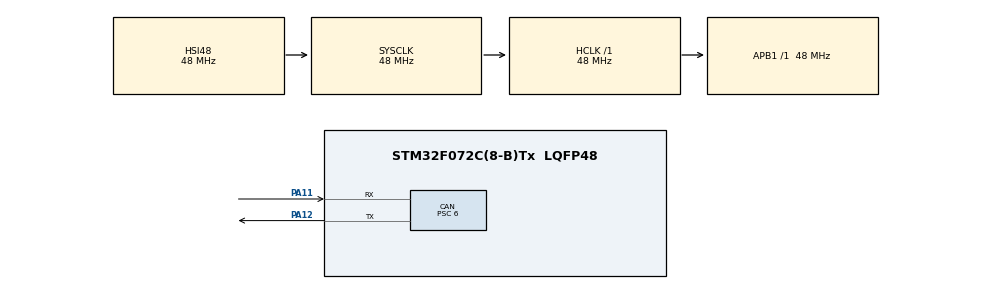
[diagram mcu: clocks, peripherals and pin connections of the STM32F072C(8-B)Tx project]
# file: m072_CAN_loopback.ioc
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CAN.BS1=CAN_BS1_13TQ
CAN.BS2=CAN_BS2_2TQ
CAN.CalculateBaudRate=500000
CAN.CalculateTimeBit=2000
CAN.CalculateTimeQuantum=125.0
CAN.Mode=CAN_MODE_LOOPBACK
CAN.Prescaler=6
Mcu.Family=STM32F0
Mcu.Name=STM32F072C(8-B)Tx
Mcu.Package=LQFP48
NVIC.CEC_CAN_IRQn=true\:0\:0\:false\:false\:true\:true\:true\:true
PA11.Mode=CAN_Activate
PA11.Signal=CAN_RX
PA12.Mode=CAN_Activate
PA12.Signal=CAN_TX
PA13.Mode=Serial_Wire
PA13.Signal=SYS_SWDIO
PA14.Mode=Serial_Wire
PA14.Signal=SYS_SWCLK
PF0-OSC_IN.Mode=HSE-External-Oscillator
PF0-OSC_IN.Signal=RCC_OSC_IN
PF1-OSC_OUT.Mode=HSE-External-Oscillator
PF1-OSC_OUT.Signal=RCC_OSC_OUT
ProjectManager.HeapSize=0x200
ProjectManager.StackSize=0x400
ProjectManager.TargetToolchain=STM32CubeIDE
RCC.AHBFreq_Value=48000000
RCC.APB1Freq_Value=48000000
RCC.APB1TimFreq_Value=48000000
RCC.HCLKFreq_Value=48000000
RCC.SYSCLKFreq_VALUE=48000000
RCC.SYSCLKSource=RCC_SYSCLKSOURCE_HSI48
board=custom

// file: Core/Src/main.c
/* USER CODE BEGIN Header */
/**
  ******************************************************************************
  * @file           : main.c
  * @brief          : Main program body
  ******************************************************************************
  * @attention
  *
  * Copyright (c) 2025 STMicroelectronics.
  * All rights reserved.
  *
  * This software is licensed under terms that can be found in the LICENSE file
  * in the root directory of this software component.
  * If no LICENSE file comes with this software, it is provided AS-IS.
  *
  ******************************************************************************
  */
/* USER CODE END Header */
#include "main.h"

/* USER CODE BEGIN Includes */

#include <string.h>

/* USER CODE END Includes */

CAN_HandleTypeDef hcan;

/* USER CODE BEGIN PV */

CAN_TxHeaderTypeDef TxHeader;
CAN_RxHeaderTypeDef RxHeader;
uint8_t TxData[8] = "STM32CAN";
uint8_t RxData[8];
uint32_t TxMailbox;

/* USER CODE END PV */

void SystemClock_Config(void);
static void MX_GPIO_Init(void);
static void MX_CAN_Init(void);

int main(void)
{

  /* MCU Configuration--------------------------------------------------------*/

  /* Reset of all peripherals, Initializes the Flash interface and the Systick. */
  HAL_Init();

  /* Configure the system clock */
  SystemClock_Config();

  /* Initialize all configured peripherals */
  MX_GPIO_Init();
  MX_CAN_Init();
  /* USER CODE BEGIN 2 */

  // Start the CAN peripheral
  HAL_CAN_Start(&hcan);

  // Enable interrupt for incoming messages
  HAL_CAN_ActivateNotification(&hcan, CAN_IT_RX_FIFO0_MSG_PENDING);

  // Configure filter to receive all messages
  CAN_FilterTypeDef sFilterConfig;
  sFilterConfig.FilterBank = 0;
  sFilterConfig.FilterMode = CAN_FILTERMODE_IDMASK;
  sFilterConfig.FilterScale = CAN_FILTERSCALE_32BIT;
  sFilterConfig.FilterIdHigh = 0x0000;
  sFilterConfig.FilterIdLow = 0x0000;
  sFilterConfig.FilterMaskIdHigh = 0x0000;
  sFilterConfig.FilterMaskIdLow = 0x0000;
  sFilterConfig.FilterFIFOAssignment = CAN_RX_FIFO0;
  sFilterConfig.FilterActivation = ENABLE;
  sFilterConfig.SlaveStartFilterBank = 14;
  HAL_CAN_ConfigFilter(&hcan, &sFilterConfig);

  // Prepare CAN message
  TxHeader.DLC = 8;
  TxHeader.IDE = CAN_ID_STD;
  TxHeader.RTR = CAN_RTR_DATA;
  TxHeader.StdId = 0x321;
  TxHeader.TransmitGlobalTime = DISABLE;

  // Send message
  if (HAL_CAN_AddTxMessage(&hcan, &TxHeader, TxData, &TxMailbox) != HAL_OK)
  {
      Error_Handler();  // Handle transmit error
  }

  /* USER CODE END 2 */

  /* Infinite loop */
  while (1)
  {

  }
}

void SystemClock_Config(void)
{
  RCC_OscInitTypeDef RCC_OscInitStruct = {0};
  RCC_ClkInitTypeDef RCC_ClkInitStruct = {0};

  /** Initializes the RCC Oscillators according to the specified parameters
  * in the RCC_OscInitTypeDef structure.
  */
  RCC_OscInitStruct.OscillatorType = RCC_OSCILLATORTYPE_HSI48;
  RCC_OscInitStruct.HSI48State = RCC_HSI48_ON;
  RCC_OscInitStruct.PLL.PLLState = RCC_PLL_NONE;
  if (HAL_RCC_OscConfig(&RCC_OscInitStruct) != HAL_OK)
  {
    Error_Handler();
  }

  /** Initializes the CPU, AHB and APB buses clocks
  */
  RCC_ClkInitStruct.ClockType = RCC_CLOCKTYPE_HCLK|RCC_CLOCKTYPE_SYSCLK
                              |RCC_CLOCKTYPE_PCLK1;
  RCC_ClkInitStruct.SYSCLKSource = RCC_SYSCLKSOURCE_HSI48;
  RCC_ClkInitStruct.AHBCLKDivider = RCC_SYSCLK_DIV1;
  RCC_ClkInitStruct.APB1CLKDivider = RCC_HCLK_DIV1;

  if (HAL_RCC_ClockConfig(&RCC_ClkInitStruct, FLASH_LATENCY_1) != HAL_OK)
  {
    Error_Handler();
  }
}

static void MX_CAN_Init(void)
{

  hcan.Instance = CAN;
  hcan.Init.Prescaler = 6;
  hcan.Init.Mode = CAN_MODE_LOOPBACK;
  hcan.Init.SyncJumpWidth = CAN_SJW_1TQ;
  hcan.Init.TimeSeg1 = CAN_BS1_13TQ;
  hcan.Init.TimeSeg2 = CAN_BS2_2TQ;
  hcan.Init.TimeTriggeredMode = DISABLE;
  hcan.Init.AutoBusOff = DISABLE;
  hcan.Init.AutoWakeUp = DISABLE;
  hcan.Init.AutoRetransmission = DISABLE;
  hcan.Init.ReceiveFifoLocked = DISABLE;
  hcan.Init.TransmitFifoPriority = DISABLE;
  if (HAL_CAN_Init(&hcan) != HAL_OK)
  {
    Error_Handler();
  }

}

static void MX_GPIO_Init(void)
{

  /* GPIO Ports Clock Enable */
  __HAL_RCC_GPIOF_CLK_ENABLE();
  __HAL_RCC_GPIOA_CLK_ENABLE();

}

/* USER CODE BEGIN 4 */

void HAL_CAN_RxFifo0MsgPendingCallback(CAN_HandleTypeDef *hcan)
{
    HAL_CAN_GetRxMessage(hcan, CAN_RX_FIFO0, &RxHeader, RxData);
    // Now RxData[] contains the received message
}

/* USER CODE END 4 */

void Error_Handler(void)
{
  __disable_irq();
  while (1)
  {
  }
}
